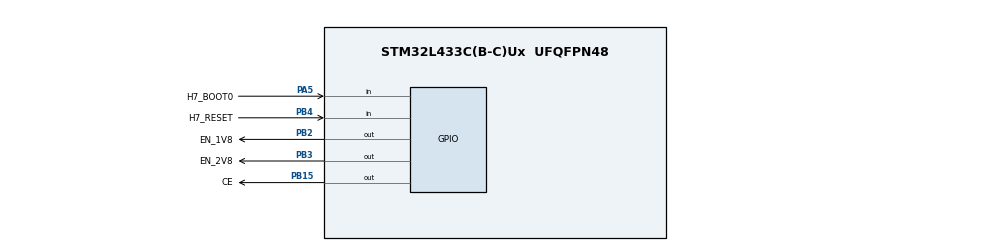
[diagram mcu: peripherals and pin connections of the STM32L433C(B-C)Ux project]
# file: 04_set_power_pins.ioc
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Mcu.Family=STM32L4
Mcu.Name=STM32L433C(B-C)Ux
Mcu.Package=UFQFPN48
NVIC.PriorityGroup=NVIC_PRIORITYGROUP_4
PA13\ (JTMS-SWDIO).Mode=Serial_Wire
PA13\ (JTMS-SWDIO).Signal=SYS_JTMS-SWDIO
PA14\ (JTCK-SWCLK).Mode=Serial_Wire
PA14\ (JTCK-SWCLK).Signal=SYS_JTCK-SWCLK
PA5.GPIO_Label=H7_BOOT0
PA5.GPIO_PuPd=GPIO_NOPULL
PA5.Signal=GPIO_Input
PB15.GPIO_Label=CE
PB15.GPIO_PuPd=GPIO_PULLDOWN
PB15.Signal=GPIO_Output
PB2.GPIO_Label=EN_1V8
PB2.GPIO_PuPd=GPIO_PULLDOWN
PB2.Signal=GPIO_Output
PB3\ (JTDO-TRACESWO).GPIO_Label=EN_2V8
PB3\ (JTDO-TRACESWO).GPIO_PuPd=GPIO_PULLDOWN
PB3\ (JTDO-TRACESWO).Signal=GPIO_Output
PB4\ (NJTRST).GPIO_Label=H7_RESET
PB4\ (NJTRST).GPIO_PuPd=GPIO_PULLDOWN
PB4\ (NJTRST).Signal=GPIO_Input
PC14-OSC32_IN\ (PC14).Mode=LSE-External-Clock-Source
PC14-OSC32_IN\ (PC14).Signal=RCC_OSC32_IN
ProjectManager.HeapSize=0x200
ProjectManager.StackSize=0x400
ProjectManager.TargetToolchain=CMake
RCC.HSE_VALUE=8000000
RCC.HSI48_VALUE=48000000
RCC.HSI_VALUE=16000000
RCC.LSE_VALUE=32768
RCC.MSI_VALUE=4000000
RCC.VCOOutputFreq_Value=32000000
board=custom

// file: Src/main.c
/* USER CODE BEGIN Header */
/**
  ******************************************************************************
  * @file           : main.c
  * @brief          : Main program body
  ******************************************************************************
  * @attention
  *
  * Copyright (c) 2025 STMicroelectronics.
  * All rights reserved.
  *
  * This software is licensed under terms that can be found in the LICENSE file
  * in the root directory of this software component.
  * If no LICENSE file comes with this software, it is provided AS-IS.
  *
  ******************************************************************************
  */
/* USER CODE END Header */
#include "main.h"

void SystemClock_Config(void);
static void MX_GPIO_Init(void);

int main(void)
{

  /* MCU Configuration--------------------------------------------------------*/

  /* Reset of all peripherals, Initializes the Flash interface and the Systick. */
  HAL_Init();

  /* Configure the system clock */
  SystemClock_Config();

  /* Initialize all configured peripherals */
  MX_GPIO_Init();
  /* USER CODE BEGIN 2 */

  /* Enable 1V8 and 2V8 power rails */
  HAL_GPIO_WritePin(EN_1V8_GPIO_Port, EN_1V8_Pin, GPIO_PIN_SET);
  HAL_GPIO_WritePin(EN_2V8_GPIO_Port, EN_2V8_Pin, GPIO_PIN_SET);

  /* USER CODE END 2 */

  /* Infinite loop */
  while (1)
  {

  }
}

void SystemClock_Config(void)
{
  RCC_OscInitTypeDef RCC_OscInitStruct = {0};
  RCC_ClkInitTypeDef RCC_ClkInitStruct = {0};

  /** Configure the main internal regulator output voltage
  */
  if (HAL_PWREx_ControlVoltageScaling(PWR_REGULATOR_VOLTAGE_SCALE1) != HAL_OK)
  {
    Error_Handler();
  }

  /** Initializes the RCC Oscillators according to the specified parameters
  * in the RCC_OscInitTypeDef structure.
  */
  RCC_OscInitStruct.OscillatorType = RCC_OSCILLATORTYPE_LSE|RCC_OSCILLATORTYPE_MSI;
  RCC_OscInitStruct.LSEState = RCC_LSE_BYPASS;
  RCC_OscInitStruct.MSIState = RCC_MSI_ON;
  RCC_OscInitStruct.MSICalibrationValue = 0;
  RCC_OscInitStruct.MSIClockRange = RCC_MSIRANGE_6;
  RCC_OscInitStruct.PLL.PLLState = RCC_PLL_NONE;
  if (HAL_RCC_OscConfig(&RCC_OscInitStruct) != HAL_OK)
  {
    Error_Handler();
  }

  /** Initializes the CPU, AHB and APB buses clocks
  */
  RCC_ClkInitStruct.ClockType = RCC_CLOCKTYPE_HCLK|RCC_CLOCKTYPE_SYSCLK
                              |RCC_CLOCKTYPE_PCLK1|RCC_CLOCKTYPE_PCLK2;
  RCC_ClkInitStruct.SYSCLKSource = RCC_SYSCLKSOURCE_MSI;
  RCC_ClkInitStruct.AHBCLKDivider = RCC_SYSCLK_DIV1;
  RCC_ClkInitStruct.APB1CLKDivider = RCC_HCLK_DIV1;
  RCC_ClkInitStruct.APB2CLKDivider = RCC_HCLK_DIV1;

  if (HAL_RCC_ClockConfig(&RCC_ClkInitStruct, FLASH_LATENCY_0) != HAL_OK)
  {
    Error_Handler();
  }

  /** Enable MSI Auto calibration
  */
  HAL_RCCEx_EnableMSIPLLMode();
}

static void MX_GPIO_Init(void)
{
  GPIO_InitTypeDef GPIO_InitStruct = {0};

  /* GPIO Ports Clock Enable */
  __HAL_RCC_GPIOC_CLK_ENABLE();
  __HAL_RCC_GPIOA_CLK_ENABLE();
  __HAL_RCC_GPIOB_CLK_ENABLE();

  /*Configure GPIO pin Output Level */
  HAL_GPIO_WritePin(GPIOB, EN_1V8_Pin|CE_Pin|EN_2V8_Pin, GPIO_PIN_RESET);

  /*Configure GPIO pin : H7_BOOT0_Pin */
  GPIO_InitStruct.Pin = H7_BOOT0_Pin;
  GPIO_InitStruct.Mode = GPIO_MODE_INPUT;
  GPIO_InitStruct.Pull = GPIO_NOPULL;
  HAL_GPIO_Init(H7_BOOT0_GPIO_Port, &GPIO_InitStruct);

  /*Configure GPIO pins : EN_1V8_Pin CE_Pin EN_2V8_Pin */
  GPIO_InitStruct.Pin = EN_1V8_Pin|CE_Pin|EN_2V8_Pin;
  GPIO_InitStruct.Mode = GPIO_MODE_OUTPUT_PP;
  GPIO_InitStruct.Pull = GPIO_PULLDOWN;
  GPIO_InitStruct.Speed = GPIO_SPEED_FREQ_LOW;
  HAL_GPIO_Init(GPIOB, &GPIO_InitStruct);

  /*Configure GPIO pin : H7_RESET_Pin */
  GPIO_InitStruct.Pin = H7_RESET_Pin;
  GPIO_InitStruct.Mode = GPIO_MODE_INPUT;
  GPIO_InitStruct.Pull = GPIO_PULLDOWN;
  HAL_GPIO_Init(H7_RESET_GPIO_Port, &GPIO_InitStruct);

}

void Error_Handler(void)
{
  __disable_irq();
  while (1)
  {
  }
}
